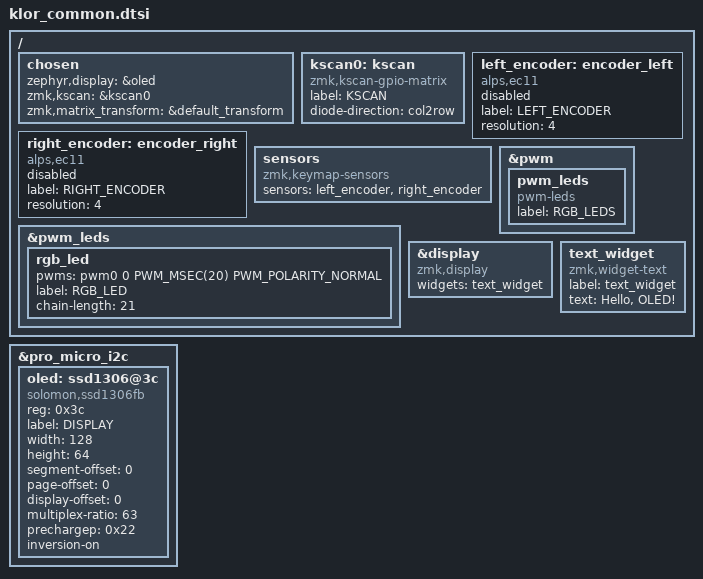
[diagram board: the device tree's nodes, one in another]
/*
 * Copyright (c) 2022 The ZMK Contributors
 *
 * SPDX-License-Identifier: MIT
 */

#include <dt-bindings/zmk/matrix_transform.h>

/ {
    chosen {
        zephyr,display = &oled;
        zmk,kscan = &kscan0;
        zmk,matrix_transform = &default_transform;
    };

    kscan0: kscan {
        compatible = "zmk,kscan-gpio-matrix";
        label = "KSCAN";
        diode-direction = "col2row";
    };

    left_encoder: encoder_left {
        compatible = "alps,ec11";
        label = "LEFT_ENCODER";
        resolution = <4>;
        status = "disabled";
    };

    right_encoder: encoder_right {
        compatible = "alps,ec11";
        label = "RIGHT_ENCODER";
        resolution = <4>;
        status = "disabled";
    };

    sensors {
        compatible = "zmk,keymap-sensors";
        sensors = <&left_encoder &right_encoder>;
    };

    &pwm {
        status = "okay";
        pwm_leds: pwm_leds{
            compatible = "pwm-leds";
            label = "RGB_LEDS";
            status = "okay";
        };
};

    &pwm_leds {
        rgb_led: rgb_led {
            pwms = <&pwm0 0 PWM_MSEC(20) PWM_POLARITY_NORMAL>;
            label = "RGB_LED";
            chain-length = <21>;
        };
    };

    &display {
        compatible = "zmk,display";
        widgets = <&text_widget>;
    };

    text_widget: text_widget {
        compatible = "zmk,widget-text";
        label = "text_widget";
        text = "Hello, OLED!";
    };
};

&pro_micro_i2c {
    status = "okay";

    oled: ssd1306@3c {
        compatible = "solomon,ssd1306fb";
        reg = <0x3c>;
        label = "DISPLAY";
        width = <128>;
        height = <64>;
        segment-offset = <0>;
        page-offset = <0>;
        display-offset = <0>;
        multiplex-ratio = <63>;
        prechargep = <0x22>;
        inversion-on;
    };
};
